VERSION ""

NS_ :

BS_:

BU_: Node1 Node2 Node3

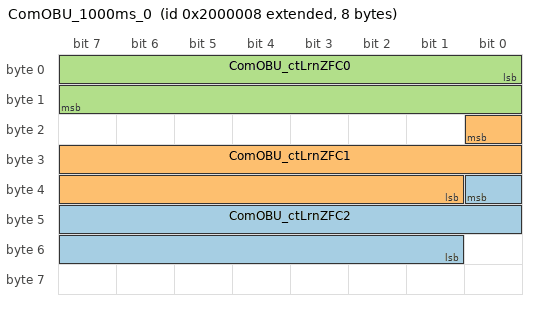
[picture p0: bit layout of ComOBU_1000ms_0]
BO_ 2181038088 ComOBU_1000ms_0: 8 CAN_IO
 SG_ ComOBU_ctLrnZFC2 : 32|16@0+ (1,0) [0|65535] "-" Node2
 SG_ ComOBU_ctLrnZFC1 : 16|16@0+ (1,0) [0|65535] "-" Node2
 SG_ ComOBU_ctLrnZFC0 : 0|16@1- (1,0) [0|65535] "-" Node2

BO_ 769 ZomOBU_1000ms_0: 8 CAN_IO
 SG_ ZomOBU_ctLrnZFC2 : 32|16@1+ (1,0) [0|65535] "-" Vector__XX2
 SG_ ZomOBU_ctLrnZFC1 : 16|16@1+ (1,0) [0|65535] "-" Vector__XX2

BA_DEF_  "BusType" STRING ;
BA_DEF_DEF_  "BusType" "CAN";
